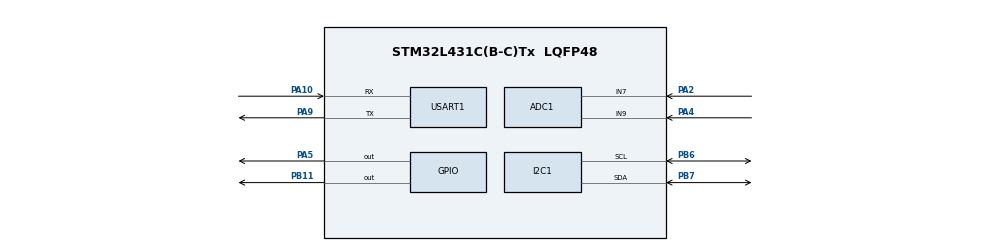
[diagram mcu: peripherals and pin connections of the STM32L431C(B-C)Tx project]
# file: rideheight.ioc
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ADC1.Channel-0\#ChannelRegularConversion=ADC_CHANNEL_9
ADC1.NbrOfConversionFlag=1
ADC1.OffsetNumber-0\#ChannelRegularConversion=ADC_OFFSET_NONE
ADC1.Rank-0\#ChannelRegularConversion=1
ADC1.SamplingTime-0\#ChannelRegularConversion=ADC_SAMPLETIME_2CYCLES_5
ADC1.master=1
I2C1.Timing=0x00100D14
Mcu.Family=STM32L4
Mcu.Name=STM32L431C(B-C)Tx
Mcu.Package=LQFP48
NVIC.PriorityGroup=NVIC_PRIORITYGROUP_4
PA10.Mode=Asynchronous
PA10.Signal=USART1_RX
PA2.Signal=ADCx_IN7
PA4.Signal=ADCx_IN9
PA5.Signal=GPIO_Output
PA9.Mode=Asynchronous
PA9.Signal=USART1_TX
PB11.Signal=GPIO_Output
PB6.Mode=I2C
PB6.Signal=I2C1_SCL
PB7.Mode=I2C
PB7.Signal=I2C1_SDA
ProjectManager.HeapSize=0x200
ProjectManager.StackSize=0x400
ProjectManager.TargetToolchain=STM32CubeIDE
RCC.ADCFreq_Value=32000000
RCC.HSE_VALUE=8000000
RCC.HSI48_VALUE=48000000
RCC.HSI_VALUE=16000000
RCC.LSE_VALUE=32768
RCC.MSI_VALUE=4000000
RCC.PLLSAI1N=16
RCC.VCOOutputFreq_Value=32000000
SH.ADCx_IN7.0=ADC1_IN7,IN7-Single-Ended
SH.ADCx_IN9.0=ADC1_IN9,IN9-Single-Ended
USART1.VirtualMode-Asynchronous=VM_ASYNC
board=custom

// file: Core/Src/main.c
/* USER CODE BEGIN Header */
/**
  ******************************************************************************
  * @file           : main.c
  * @brief          : Main program body
  ******************************************************************************
  * @attention
  *
  * Copyright (c) 2026 STMicroelectronics.
  * All rights reserved.
  *
  * This software is licensed under terms that can be found in the LICENSE file
  * in the root directory of this software component.
  * If no LICENSE file comes with this software, it is provided AS-IS.
  *
  ******************************************************************************
  */
/* USER CODE END Header */
#include "main.h"

/* USER CODE BEGIN Includes */
#include <stdio.h>
#include <string.h>
/* USER CODE END Includes */

ADC_HandleTypeDef hadc1;

I2C_HandleTypeDef hi2c1;

UART_HandleTypeDef huart1;

void SystemClock_Config(void);
static void MX_GPIO_Init(void);
static void MX_ADC1_Init(void);
static void MX_USART1_UART_Init(void);
static void MX_I2C1_Init(void);

int main(void)
{

  /* MCU Configuration--------------------------------------------------------*/

  /* Reset of all peripherals, Initializes the Flash interface and the Systick. */
  HAL_Init();

  /* Configure the system clock */
  SystemClock_Config();

  /* Initialize all configured peripherals */
  MX_GPIO_Init();
  MX_ADC1_Init();
  MX_USART1_UART_Init();
  MX_I2C1_Init();

  /* Infinite loop */
  /* USER CODE BEGIN WHILE */
  // uint32_t adc_val = 0;
  uint16_t ir_addr = 0x52;
  char msg[64];
  HAL_GPIO_TogglePin(GPIOB,GPIO_PIN_6);
    while (1)
    {
  	  HAL_GPIO_TogglePin(GPIOB, GPIO_PIN_11);
  	  HAL_GPIO_TogglePin(GPIOA, GPIO_PIN_5);

      if (HAL_I2C_IsDeviceReady(&hi2c1, ir_addr, 3, 100) == HAL_OK) {
          int len = sprintf(msg, "VL53L0X Ping OK (Addr: 0x%02X)\r\n", ir_addr);
          HAL_UART_Transmit(&huart1, (uint8_t*)msg, len, 100);
      }
      else {
          int len = sprintf(msg, "VL53L0X Ping FAILED\r\n");
          HAL_UART_Transmit(&huart1, (uint8_t*)msg, len, 100);
      }
      HAL_Delay(100);
    }
    /* USER CODE END WHILE */

}

void SystemClock_Config(void)
{
  RCC_OscInitTypeDef RCC_OscInitStruct = {0};
  RCC_ClkInitTypeDef RCC_ClkInitStruct = {0};

  /** Configure the main internal regulator output voltage
  */
  if (HAL_PWREx_ControlVoltageScaling(PWR_REGULATOR_VOLTAGE_SCALE1) != HAL_OK)
  {
    Error_Handler();
  }

  /** Initializes the RCC Oscillators according to the specified parameters
  * in the RCC_OscInitTypeDef structure.
  */
  RCC_OscInitStruct.OscillatorType = RCC_OSCILLATORTYPE_MSI;
  RCC_OscInitStruct.MSIState = RCC_MSI_ON;
  RCC_OscInitStruct.MSICalibrationValue = 0;
  RCC_OscInitStruct.MSIClockRange = RCC_MSIRANGE_6;
  RCC_OscInitStruct.PLL.PLLState = RCC_PLL_NONE;
  if (HAL_RCC_OscConfig(&RCC_OscInitStruct) != HAL_OK)
  {
    Error_Handler();
  }

  /** Initializes the CPU, AHB and APB buses clocks
  */
  RCC_ClkInitStruct.ClockType = RCC_CLOCKTYPE_HCLK|RCC_CLOCKTYPE_SYSCLK
                              |RCC_CLOCKTYPE_PCLK1|RCC_CLOCKTYPE_PCLK2;
  RCC_ClkInitStruct.SYSCLKSource = RCC_SYSCLKSOURCE_MSI;
  RCC_ClkInitStruct.AHBCLKDivider = RCC_SYSCLK_DIV1;
  RCC_ClkInitStruct.APB1CLKDivider = RCC_HCLK_DIV1;
  RCC_ClkInitStruct.APB2CLKDivider = RCC_HCLK_DIV1;

  if (HAL_RCC_ClockConfig(&RCC_ClkInitStruct, FLASH_LATENCY_0) != HAL_OK)
  {
    Error_Handler();
  }
}

static void MX_ADC1_Init(void)
{

  ADC_ChannelConfTypeDef sConfig = {0};

  /** Common config
  */
  hadc1.Instance = ADC1;
  hadc1.Init.ClockPrescaler = ADC_CLOCK_ASYNC_DIV1;
  hadc1.Init.Resolution = ADC_RESOLUTION_12B;
  hadc1.Init.DataAlign = ADC_DATAALIGN_RIGHT;
  hadc1.Init.ScanConvMode = ADC_SCAN_DISABLE;
  hadc1.Init.EOCSelection = ADC_EOC_SINGLE_CONV;
  hadc1.Init.LowPowerAutoWait = DISABLE;
  hadc1.Init.ContinuousConvMode = DISABLE;
  hadc1.Init.NbrOfConversion = 1;
  hadc1.Init.DiscontinuousConvMode = DISABLE;
  hadc1.Init.ExternalTrigConv = ADC_SOFTWARE_START;
  hadc1.Init.ExternalTrigConvEdge = ADC_EXTERNALTRIGCONVEDGE_NONE;
  hadc1.Init.DMAContinuousRequests = DISABLE;
  hadc1.Init.Overrun = ADC_OVR_DATA_PRESERVED;
  hadc1.Init.OversamplingMode = DISABLE;
  if (HAL_ADC_Init(&hadc1) != HAL_OK)
  {
    Error_Handler();
  }

  /** Configure Regular Channel
  */
  sConfig.Channel = ADC_CHANNEL_9;
  sConfig.Rank = ADC_REGULAR_RANK_1;
  sConfig.SamplingTime = ADC_SAMPLETIME_2CYCLES_5;
  sConfig.SingleDiff = ADC_SINGLE_ENDED;
  sConfig.OffsetNumber = ADC_OFFSET_NONE;
  sConfig.Offset = 0;
  if (HAL_ADC_ConfigChannel(&hadc1, &sConfig) != HAL_OK)
  {
    Error_Handler();
  }

}

static void MX_I2C1_Init(void)
{

  hi2c1.Instance = I2C1;
  hi2c1.Init.Timing = 0x00100D14;
  hi2c1.Init.OwnAddress1 = 0;
  hi2c1.Init.AddressingMode = I2C_ADDRESSINGMODE_7BIT;
  hi2c1.Init.DualAddressMode = I2C_DUALADDRESS_DISABLE;
  hi2c1.Init.OwnAddress2 = 0;
  hi2c1.Init.OwnAddress2Masks = I2C_OA2_NOMASK;
  hi2c1.Init.GeneralCallMode = I2C_GENERALCALL_DISABLE;
  hi2c1.Init.NoStretchMode = I2C_NOSTRETCH_DISABLE;
  if (HAL_I2C_Init(&hi2c1) != HAL_OK)
  {
    Error_Handler();
  }

  /** Configure Analogue filter
  */
  if (HAL_I2CEx_ConfigAnalogFilter(&hi2c1, I2C_ANALOGFILTER_ENABLE) != HAL_OK)
  {
    Error_Handler();
  }

  /** Configure Digital filter
  */
  if (HAL_I2CEx_ConfigDigitalFilter(&hi2c1, 0) != HAL_OK)
  {
    Error_Handler();
  }

}

static void MX_USART1_UART_Init(void)
{

  huart1.Instance = USART1;
  huart1.Init.BaudRate = 115200;
  huart1.Init.WordLength = UART_WORDLENGTH_8B;
  huart1.Init.StopBits = UART_STOPBITS_1;
  huart1.Init.Parity = UART_PARITY_NONE;
  huart1.Init.Mode = UART_MODE_TX_RX;
  huart1.Init.HwFlowCtl = UART_HWCONTROL_NONE;
  huart1.Init.OverSampling = UART_OVERSAMPLING_16;
  huart1.Init.OneBitSampling = UART_ONE_BIT_SAMPLE_DISABLE;
  huart1.AdvancedInit.AdvFeatureInit = UART_ADVFEATURE_NO_INIT;
  if (HAL_UART_Init(&huart1) != HAL_OK)
  {
    Error_Handler();
  }

}

static void MX_GPIO_Init(void)
{
  GPIO_InitTypeDef GPIO_InitStruct = {0};

  /* GPIO Ports Clock Enable */
  __HAL_RCC_GPIOA_CLK_ENABLE();
  __HAL_RCC_GPIOB_CLK_ENABLE();

  /*Configure GPIO pin Output Level */
  HAL_GPIO_WritePin(GPIOA, GPIO_PIN_5, GPIO_PIN_RESET);

  /*Configure GPIO pin Output Level */
  HAL_GPIO_WritePin(GPIOB, GPIO_PIN_11, GPIO_PIN_RESET);

  /*Configure GPIO pin : PA5 */
  GPIO_InitStruct.Pin = GPIO_PIN_5;
  GPIO_InitStruct.Mode = GPIO_MODE_OUTPUT_PP;
  GPIO_InitStruct.Pull = GPIO_NOPULL;
  GPIO_InitStruct.Speed = GPIO_SPEED_FREQ_LOW;
  HAL_GPIO_Init(GPIOA, &GPIO_InitStruct);

  /*Configure GPIO pin : PB11 */
  GPIO_InitStruct.Pin = GPIO_PIN_11;
  GPIO_InitStruct.Mode = GPIO_MODE_OUTPUT_PP;
  GPIO_InitStruct.Pull = GPIO_NOPULL;
  GPIO_InitStruct.Speed = GPIO_SPEED_FREQ_LOW;
  HAL_GPIO_Init(GPIOB, &GPIO_InitStruct);

}

void Error_Handler(void)
{
  __disable_irq();
  while (1)
  {
  }
}
